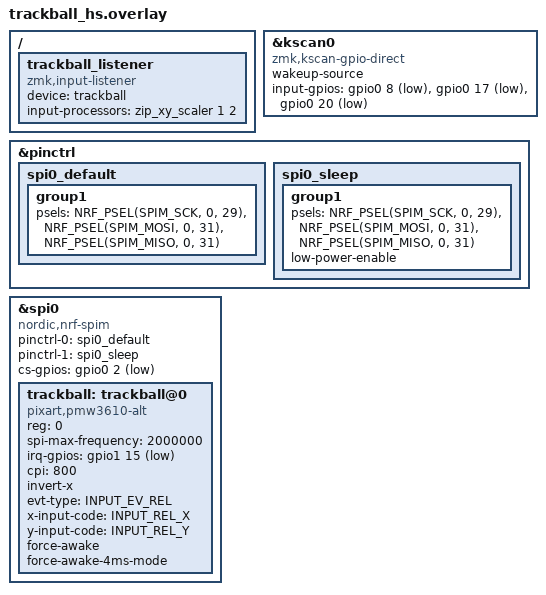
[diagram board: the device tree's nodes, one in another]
/*
 * Copyright (c) 2021-2022 The ZMK Contributors
 *
 * SPDX-License-Identifier: MIT
 *
 * connections to breakout board https://github.com/siderakb/pmw3610-pcb
 * 115 - motion
 * 002 - nCS (sel)
 * 029 - sclk 
 * 031 - sdio (MOSI/MISO)
 * vcc - vcc
 * gnd - gnd
 *
 * Buttons:
 * 008 to gnd - LMB
 * 017 to gnd - MMB
 * 020 to gnd - RMB
 */

#include "trackball_hs.dtsi" 

&kscan0 {
        compatible = "zmk,kscan-gpio-direct";
        wakeup-source;
        input-gpios
            = <&gpio0 8 (GPIO_ACTIVE_LOW | GPIO_PULL_UP)>
            , <&gpio0 17 (GPIO_ACTIVE_LOW | GPIO_PULL_UP)>
            , <&gpio0 20 (GPIO_ACTIVE_LOW | GPIO_PULL_UP)>
            ;
    };

&pinctrl {
    spi0_default: spi0_default {
        group1 {
            psels = <NRF_PSEL(SPIM_SCK, 0, 29)>,
                <NRF_PSEL(SPIM_MOSI, 0, 31)>,
                <NRF_PSEL(SPIM_MISO, 0, 31)>;
        };
    };

    spi0_sleep: spi0_sleep {
        group1 {
            psels = <NRF_PSEL(SPIM_SCK, 0, 29)>,
                <NRF_PSEL(SPIM_MOSI, 0, 31)>,
                <NRF_PSEL(SPIM_MISO, 0, 31)>;
            low-power-enable;
        };
    };
};

#include <zephyr/dt-bindings/input/input-event-codes.h>

&spi0 {
    status = "okay";
    compatible = "nordic,nrf-spim";
    pinctrl-0 = <&spi0_default>;
    pinctrl-1 = <&spi0_sleep>;
    pinctrl-names = "default", "sleep";
    cs-gpios = <&gpio0 2 GPIO_ACTIVE_LOW>;

    trackball: trackball@0 {
        status = "okay";
        compatible = "pixart,pmw3610-alt";
        reg = <0>;
        spi-max-frequency = <2000000>;
        irq-gpios =<&gpio1 15 (GPIO_ACTIVE_LOW | GPIO_PULL_UP)>;
        cpi = <800>;
        // swap-xy; /* optional */
        invert-x; /* optional */
        // invert-y; /* optional */
        evt-type = <INPUT_EV_REL>;
        x-input-code = <INPUT_REL_X>;
        y-input-code = <INPUT_REL_Y>;

        force-awake;
        /* keep the sensor awake while ZMK activity state is ACTIVE,
           fallback to normal downshift mode after ZMK goes into IDLE / SLEEP mode.
           thus, the sensor would be a `wakeup-source` */

        force-awake-4ms-mode;
        /* while force-awake is acitvated, enable this mode to force sampling per 
           4ms, where the default sampling rate is 8ms. */
        /* NOTE: apply this mode if you need 250Hz with direct USB connection. */
    };
};

#include <dt-bindings/zmk/input_transform.h>
#include <input/processors.dtsi>

/ {
  trackball_listener {
    compatible = "zmk,input-listener";
    device = <&trackball>;
    # input-processors = <&zip_xy_scaler 1 2>;
  };
};
